# S32R372 register map
Vendor: Freescale Semiconductor, Inc.; Series: Qorivva; File version: 1.6
Registers are 32-bit, read-write, reset 0x0 unless marked. A register's access mark holds for its fields unless they carry their own. Offsets are from the block's base; [hi:lo] are bit positions; 'fields as' and 'values as' point back to an identical list.

## MCB — Multipurpose registers
Base 0xFFC0C000; register names take the prefix MCB_
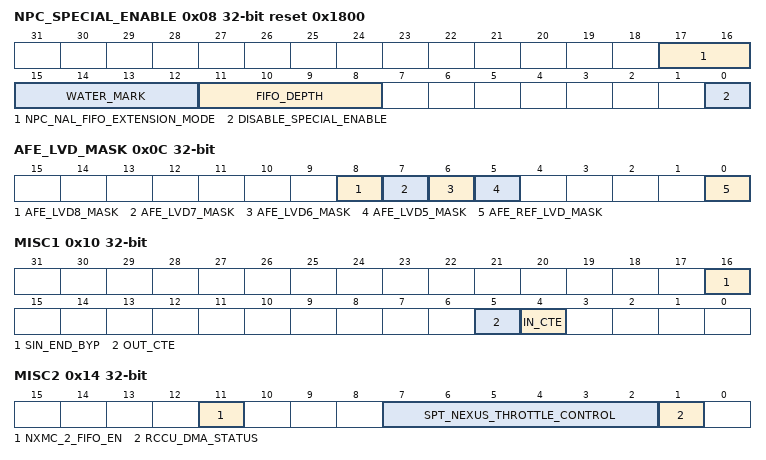
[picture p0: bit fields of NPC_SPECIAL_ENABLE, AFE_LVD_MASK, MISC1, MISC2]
0x08 NPC_SPECIAL_ENABLE reset 0x1800 — NPC Special Enable Control
  [17:16] NPC_NAL_FIFO_EXTENSION_MODE
    0=Disable NAL_NPC Extended fifo mode; 3=Enable NAL_NPC Extended fifo mode. Extends NAL existing fifo to make it 15 words deep. Set this bit prior to starting a NAL-NPC transaction. In this mode MCB_NPC_SPECIAL_ENABLE[WATER_MARK] should be configured to 4'b0101 or lower and MCB_NPC_SPECIAL_ENABLE[FIFO_DEPTH] should be programmed to 4'b1110
  [15:12] WATER_MARK — WATER MARK LEVEL
  [11:8] FIFO_DEPTH — NAL FIFO DEPTH
  [0] DISABLE_SPECIAL_ENABLE — Disable special enable functionality of NPC auxiliary ports
    0=Enable Special Enable functionality of NPC auxiliary ports; 1=Disable Special Enable functionality of NPC auxiliary ports
0x0C AFE_LVD_MASK
  [8] AFE_LVD8_MASK — Mask LVD on level shifter logic
    1=Donot Mask LVD on level shifter logic; 0=Mask LVD on level shifter logic
  [7] AFE_LVD7_MASK — Mask LVD on AFE SDPLL digital circuitry
    1=Not Mask LVD on AFE SDPLL digital circuitry; 0=Mask LVD on AFE SDPLL digital circuitry
  [6] AFE_LVD6_MASK — Mask LVD on AFE SDPLL analog circuitry
    1=Not Mask LVD on AFE SDPLL analog circuitry; 0=Mask LVD on AFE SDPLL analog circuitry
  [5] AFE_LVD5_MASK — Mask LVD on AFE OSC circuitry
    1=Not Mask LVD on AFE OSC circuitry; 0=Mask LVD on AFE OSC circuitry
  [0] AFE_REF_LVD_MASK — Mask LVD on VDD_HV_RAW
    1=Not Mask LVD on AFE reference voltage; 0=Mask LVD on AFE reference voltage
0x10 MISC1 — Miscellaneous 1 register
  [16] SIN_END_BYP — single ended bypass
    0=XOSC Single Ended Bypass mode is not used; 1=XOSC Single Ended Bypass mode is used
  [5] OUT_CTE — To select the RCS/RFS outputs from CTE.
    0=From PAD. Refer the "IO Signal Description and Input multiplexing tables" spreadsheet attached with this document.; 1=HSYNC/VSYNC from MIPICSI-2
  [4] IN_CTE — To select the RCS/RFS inputs to CTE.
    values as OUT_CTE
0x14 MISC2 — Miscellaneous 2 Register
  [11] NXMC_2_FIFO_EN — Enable signal for NXMC_2 FIFO
    0=NXMC_2 snoops SPT data directly; 1=SPT AHB interface signals are captured in a FIFO. NXMC_2 receives data from this FIFO's output interface.
  [7:2] SPT_NEXUS_THROTTLE_CONTROL
  [1] RCCU_DMA_STATUS ro
    0=DMA RCCU is not active; 1=DMA RCCU is active
0x18 MISC3 — Miscellaneous 3 Register
  [31:2] POR_REN — Power retention
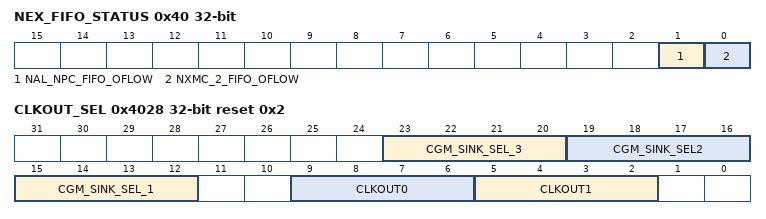
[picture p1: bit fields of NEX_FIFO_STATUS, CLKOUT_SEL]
0x40 NEX_FIFO_STATUS — Nexus Trace Fifo Status Register
  [1] NAL_NPC_FIFO_OFLOW — Overflow status of NAL_NPC Extended fifo
    0=No overflow has occured in NAL_NPC Extended fifo; 1=NAL_NPC Extended fifo has overflown
  [0] NXMC_2_FIFO_OFLOW — Overflow status of NXMC_2_FIFO
    0=No overflow has occured in NXMC_2_FIFO; 1=NXMC_2_FIFO has overflown
0x4028 CLKOUT_SEL reset 0x2 — CLKOUT Source Select
  [23:20] CGM_SINK_SEL_3 — Clocks mux selection For MCB_CLKOUT_SEL[CLKOUT 0] - Clock selected by CGM_SINK_SEL_3 For MCB_CLKOUT_SEL[CLKOUT 1] - Clock selected by CGM_SINK_SEL_3
    0=SYS_CLK; 1=CORE1_CLK; 2=CORE2_CLK; 3=PBRIDGE_0/1_CLK; 4=DMA_CLK; 6=SYS_CLK; 7=SYS_CLK; 8=PBRIDGE_0/1_CLK; 9=PBRIDGE_0/1_CLK; 10=PBRIDGE_0/1_CLK; 11=Core_1 TCK; 12=Core_2 TCK; 13=Flash clock; 15=Enable signal to flash to generate internal clock based on flash clock
  [19:16] CGM_SINK_SEL2 — Clocks mux selection For MCB_CLKOUT_SEL[CLKOUT 0] - Clock selected by CGM_SINK_SEL_2 For MCB_CLKOUT_SEL[CLKOUT 1] - Clock selected by CGM_SINK_SEL_2
    0=ADC_CLK; 1=ADC_CLK; 3=CAN_CLK_OUT; 4=SPT_CLK; 8=SPI_CLK; 9=LIN_CLK; 12=Core_1 m_clk/nex_clk; 13=Core_1 slv_clk; 14=Core_2 m_clk/nex_clk; 15=Core_2 slv_clk
  [15:12] CGM_SINK_SEL_1 — Clocks mux selection For MCB_CLKOUT_SEL[CLKOUT 0] - Clock selected by CGM_SINK_SEL_1 For MCB_CLKOUT_SEL[CLKOUT 1] - Clock selected by CGM_SINK_SEL_1
    0=CGM CLK_AUX[0]; 2=CGM CLK_AUX[2]; 3=CGM CLK_AUX[3]; 4=CGM CLK_AUX[4]; 7=CGM CLK_AUX[7]; 12=CGM CLK_AUX[12]; 13=CGM CLK_AUX[13]; 15=CGM CLK_SYS
  [9:6] CLKOUT0 — Clock Out
    0=RCOSC Clock; 1=XOSC Clock (Test Mode use of XOSC_CLK); 2=PLL0 PHI Clock; 3=AFE 160 MHz Clock (NOTE: divide in MC_AUX_DIV before use); 4=PLL1 PHI Clock; 5=NAP/NAL Clock; 6=OSC_40MHz (XOSC_CLK); 8=CTE divided Clock; 9=PLL0 FBCLOCKIN IN PLL 1:1 mode; 10=AFE 320 MHZ Clock; 11=AFE 80 MHZ Clock; 13=Clock selected by CGM_SINK_SEL_1; 14=Clock selected by CGM_SINK_SEL_2; 15=Clock selected by CGM_SINK_SEL_3
  [5:2] CLKOUT1 — Same options as for CLKOUT0
